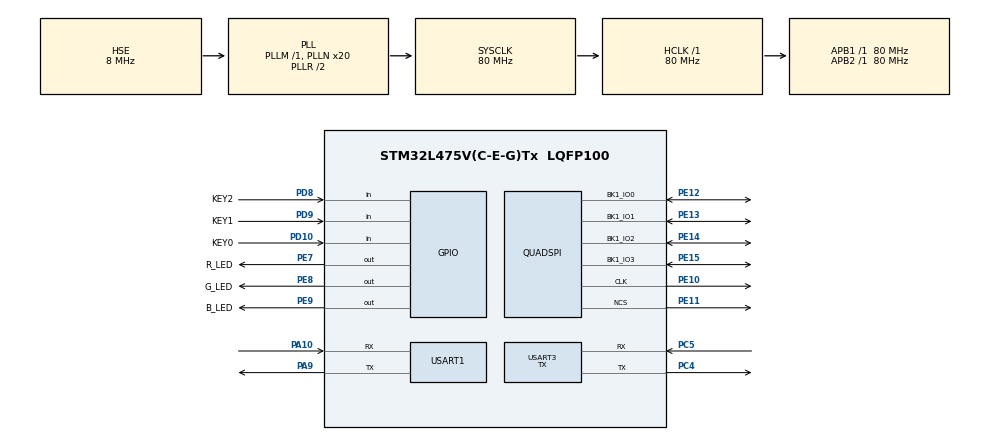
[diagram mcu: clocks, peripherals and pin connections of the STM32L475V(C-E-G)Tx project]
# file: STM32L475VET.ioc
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Dma.Request0=USART1_RX
Dma.Request1=USART1_TX
Dma.USART1_RX.0.Direction=DMA_PERIPH_TO_MEMORY
Dma.USART1_RX.0.Instance=DMA1_Channel5
Dma.USART1_RX.0.MemDataAlignment=DMA_MDATAALIGN_BYTE
Dma.USART1_RX.0.MemInc=DMA_MINC_ENABLE
Dma.USART1_RX.0.Mode=DMA_CIRCULAR
Dma.USART1_RX.0.PeriphDataAlignment=DMA_PDATAALIGN_BYTE
Dma.USART1_RX.0.PeriphInc=DMA_PINC_DISABLE
Dma.USART1_RX.0.Priority=DMA_PRIORITY_MEDIUM
Dma.USART1_TX.1.Direction=DMA_MEMORY_TO_PERIPH
Dma.USART1_TX.1.Instance=DMA1_Channel4
Dma.USART1_TX.1.MemDataAlignment=DMA_MDATAALIGN_BYTE
Dma.USART1_TX.1.MemInc=DMA_MINC_ENABLE
Dma.USART1_TX.1.Mode=DMA_NORMAL
Dma.USART1_TX.1.PeriphDataAlignment=DMA_PDATAALIGN_BYTE
Dma.USART1_TX.1.PeriphInc=DMA_PINC_DISABLE
Dma.USART1_TX.1.Priority=DMA_PRIORITY_LOW
Mcu.Family=STM32L4
Mcu.Name=STM32L475V(C-E-G)Tx
Mcu.Package=LQFP100
NVIC.DMA1_Channel4_IRQn=true\:1\:0\:true\:false\:false\:false\:true\:true
NVIC.DMA1_Channel5_IRQn=true\:1\:0\:true\:false\:false\:false\:true\:true
NVIC.PriorityGroup=NVIC_PRIORITYGROUP_4
NVIC.USART1_IRQn=true\:1\:0\:true\:false\:false\:true\:true\:true
PA10.Mode=Asynchronous
PA10.Signal=USART1_RX
PA13\ (JTMS-SWDIO).Mode=Serial_Wire
PA13\ (JTMS-SWDIO).Signal=SYS_JTMS-SWDIO
PA14\ (JTCK-SWCLK).Mode=Serial_Wire
PA14\ (JTCK-SWCLK).Signal=SYS_JTCK-SWCLK
PA9.Mode=Asynchronous
PA9.Signal=USART1_TX
PC4.Mode=Asynchronous
PC4.Signal=USART3_TX
PC5.Mode=Asynchronous
PC5.Signal=USART3_RX
PD10.GPIO_Label=KEY0
PD10.Signal=GPIO_Input
PD8.GPIO_Label=KEY2
PD8.Signal=GPIO_Input
PD9.GPIO_Label=KEY1
PD9.Signal=GPIO_Input
PE10.Mode=Single Bank
PE10.Signal=QUADSPI_CLK
PE11.Mode=Single Bank
PE11.Signal=QUADSPI_NCS
PE12.Mode=Single Bank
PE12.Signal=QUADSPI_BK1_IO0
PE13.Mode=Single Bank
PE13.Signal=QUADSPI_BK1_IO1
PE14.Mode=Single Bank
PE14.Signal=QUADSPI_BK1_IO2
PE15.Mode=Single Bank
PE15.Signal=QUADSPI_BK1_IO3
PE7.GPIO_Label=R_LED
PE7.GPIO_ModeDefaultOutputPP=GPIO_MODE_OUTPUT_PP
PE7.GPIO_PuPd=GPIO_NOPULL
PE7.GPIO_Speed=GPIO_SPEED_FREQ_HIGH
PE7.PinState=GPIO_PIN_SET
PE7.Signal=GPIO_Output
PE8.GPIO_Label=G_LED
PE8.GPIO_ModeDefaultOutputPP=GPIO_MODE_OUTPUT_PP
PE8.GPIO_PuPd=GPIO_NOPULL
PE8.GPIO_Speed=GPIO_SPEED_FREQ_HIGH
PE8.PinState=GPIO_PIN_SET
PE8.Signal=GPIO_Output
PE9.GPIO_Label=B_LED
PE9.GPIO_ModeDefaultOutputPP=GPIO_MODE_OUTPUT_PP
PE9.GPIO_PuPd=GPIO_NOPULL
PE9.GPIO_Speed=GPIO_SPEED_FREQ_HIGH
PE9.PinState=GPIO_PIN_SET
PE9.Signal=GPIO_Output
PH0-OSC_IN\ (PH0).Mode=HSE-External-Oscillator
PH0-OSC_IN\ (PH0).Signal=RCC_OSC_IN
PH1-OSC_OUT\ (PH1).Mode=HSE-External-Oscillator
PH1-OSC_OUT\ (PH1).Signal=RCC_OSC_OUT
ProjectManager.HeapSize=0x200
ProjectManager.StackSize=0x400
ProjectManager.TargetToolchain=MDK-ARM V5.32
QUADSPI.ChipSelectHighTime-Single\ Bank=QSPI_CS_HIGH_TIME_1_CYCLE
QUADSPI.ClockPrescaler-Single\ Bank=1
QUADSPI.FifoThreshold-Single\ Bank=1
QUADSPI.FlashSize-Single\ Bank=23
QUADSPI.SampleShifting-Single\ Bank=QSPI_SAMPLE_SHIFTING_HALFCYCLE
RCC.ADCFreq_Value=32000000
RCC.AHBFreq_Value=80000000
RCC.APB1Freq_Value=80000000
RCC.APB1TimFreq_Value=80000000
RCC.APB2Freq_Value=80000000
RCC.APB2TimFreq_Value=80000000
RCC.CortexFreq_Value=80000000
RCC.HCLKFreq_Value=80000000
RCC.HSE_VALUE=8000000
RCC.HSI_VALUE=16000000
RCC.LSE_VALUE=32768
RCC.MSI_VALUE=4000000
RCC.PLLN=20
RCC.PLLSourceVirtual=RCC_PLLSOURCE_HSE
RCC.SYSCLKFreq_VALUE=80000000
RCC.SYSCLKSource=RCC_SYSCLKSOURCE_PLLCLK
RCC.USBFreq_Value=32000000
RCC.VCOOutputFreq_Value=160000000
USART1.VirtualMode-Asynchronous=VM_ASYNC
USART3.Mode=MODE_TX
USART3.VirtualMode-Asynchronous=VM_ASYNC
board=custom

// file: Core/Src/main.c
/* USER CODE BEGIN Header */
/**
  ******************************************************************************
  * @file           : main.c
  * @brief          : Main program body
  ******************************************************************************
  * @attention
  *
  * Copyright (c) 2023 STMicroelectronics.
  * All rights reserved.
  *
  * This software is licensed under terms that can be found in the LICENSE file
  * in the root directory of this software component.
  * If no LICENSE file comes with this software, it is provided AS-IS.
  *
  ******************************************************************************
  */
/* USER CODE END Header */
#include "main.h"

QSPI_HandleTypeDef hqspi;

UART_HandleTypeDef huart1;
UART_HandleTypeDef huart3;
DMA_HandleTypeDef hdma_usart1_rx;
DMA_HandleTypeDef hdma_usart1_tx;

void SystemClock_Config(void);
static void MX_GPIO_Init(void);
static void MX_DMA_Init(void);
static void MX_USART1_UART_Init(void);
static void MX_USART3_UART_Init(void);
static void MX_QUADSPI_Init(void);
/* USER CODE BEGIN PFP */
extern void System_Init(void);
extern void APP_Init(void);
extern void APP_Running(void);
/* USER CODE END PFP */

int main(void)
{

  /* MCU Configuration--------------------------------------------------------*/

  /* Reset of all peripherals, Initializes the Flash interface and the Systick. */
  HAL_Init();

  /* Configure the system clock */
  SystemClock_Config();

  /* USER CODE BEGIN SysInit */
  System_Init();
  /* USER CODE END SysInit */

  /* Initialize all configured peripherals */
  MX_GPIO_Init();
  MX_DMA_Init();
  MX_USART1_UART_Init();
  MX_USART3_UART_Init();
  MX_QUADSPI_Init();
  /* USER CODE BEGIN 2 */
  APP_Init();
  /* USER CODE END 2 */

  /* Infinite loop */
  while (1)
  {

    /* USER CODE BEGIN 3 */
    APP_Running();
  }
  /* USER CODE END 3 */
}

void SystemClock_Config(void)
{
  RCC_OscInitTypeDef RCC_OscInitStruct = {0};
  RCC_ClkInitTypeDef RCC_ClkInitStruct = {0};

  /** Configure the main internal regulator output voltage
  */
  if (HAL_PWREx_ControlVoltageScaling(PWR_REGULATOR_VOLTAGE_SCALE1) != HAL_OK)
  {
    Error_Handler();
  }

  /** Initializes the RCC Oscillators according to the specified parameters
  * in the RCC_OscInitTypeDef structure.
  */
  RCC_OscInitStruct.OscillatorType = RCC_OSCILLATORTYPE_HSE;
  RCC_OscInitStruct.HSEState = RCC_HSE_ON;
  RCC_OscInitStruct.PLL.PLLState = RCC_PLL_ON;
  RCC_OscInitStruct.PLL.PLLSource = RCC_PLLSOURCE_HSE;
  RCC_OscInitStruct.PLL.PLLM = 1;
  RCC_OscInitStruct.PLL.PLLN = 20;
  RCC_OscInitStruct.PLL.PLLP = RCC_PLLP_DIV7;
  RCC_OscInitStruct.PLL.PLLQ = RCC_PLLQ_DIV2;
  RCC_OscInitStruct.PLL.PLLR = RCC_PLLR_DIV2;
  if (HAL_RCC_OscConfig(&RCC_OscInitStruct) != HAL_OK)
  {
    Error_Handler();
  }

  /** Initializes the CPU, AHB and APB buses clocks
  */
  RCC_ClkInitStruct.ClockType = RCC_CLOCKTYPE_HCLK|RCC_CLOCKTYPE_SYSCLK
                              |RCC_CLOCKTYPE_PCLK1|RCC_CLOCKTYPE_PCLK2;
  RCC_ClkInitStruct.SYSCLKSource = RCC_SYSCLKSOURCE_PLLCLK;
  RCC_ClkInitStruct.AHBCLKDivider = RCC_SYSCLK_DIV1;
  RCC_ClkInitStruct.APB1CLKDivider = RCC_HCLK_DIV1;
  RCC_ClkInitStruct.APB2CLKDivider = RCC_HCLK_DIV1;

  if (HAL_RCC_ClockConfig(&RCC_ClkInitStruct, FLASH_LATENCY_4) != HAL_OK)
  {
    Error_Handler();
  }
}

static void MX_QUADSPI_Init(void)
{

  /* QUADSPI parameter configuration*/
  hqspi.Instance = QUADSPI;
  hqspi.Init.ClockPrescaler = 1;
  hqspi.Init.FifoThreshold = 1;
  hqspi.Init.SampleShifting = QSPI_SAMPLE_SHIFTING_HALFCYCLE;
  hqspi.Init.FlashSize = 23;
  hqspi.Init.ChipSelectHighTime = QSPI_CS_HIGH_TIME_1_CYCLE;
  hqspi.Init.ClockMode = QSPI_CLOCK_MODE_0;
  if (HAL_QSPI_Init(&hqspi) != HAL_OK)
  {
    Error_Handler();
  }

}

static void MX_USART1_UART_Init(void)
{

  huart1.Instance = USART1;
  huart1.Init.BaudRate = 115200;
  huart1.Init.WordLength = UART_WORDLENGTH_8B;
  huart1.Init.StopBits = UART_STOPBITS_1;
  huart1.Init.Parity = UART_PARITY_NONE;
  huart1.Init.Mode = UART_MODE_TX_RX;
  huart1.Init.HwFlowCtl = UART_HWCONTROL_NONE;
  huart1.Init.OverSampling = UART_OVERSAMPLING_16;
  huart1.Init.OneBitSampling = UART_ONE_BIT_SAMPLE_DISABLE;
  huart1.AdvancedInit.AdvFeatureInit = UART_ADVFEATURE_NO_INIT;
  if (HAL_UART_Init(&huart1) != HAL_OK)
  {
    Error_Handler();
  }

}

static void MX_USART3_UART_Init(void)
{

  huart3.Instance = USART3;
  huart3.Init.BaudRate = 115200;
  huart3.Init.WordLength = UART_WORDLENGTH_8B;
  huart3.Init.StopBits = UART_STOPBITS_1;
  huart3.Init.Parity = UART_PARITY_NONE;
  huart3.Init.Mode = UART_MODE_TX;
  huart3.Init.HwFlowCtl = UART_HWCONTROL_NONE;
  huart3.Init.OverSampling = UART_OVERSAMPLING_16;
  huart3.Init.OneBitSampling = UART_ONE_BIT_SAMPLE_DISABLE;
  huart3.AdvancedInit.AdvFeatureInit = UART_ADVFEATURE_NO_INIT;
  if (HAL_UART_Init(&huart3) != HAL_OK)
  {
    Error_Handler();
  }

}

static void MX_DMA_Init(void)
{

  /* DMA controller clock enable */
  __HAL_RCC_DMA1_CLK_ENABLE();

  /* DMA interrupt init */
  /* DMA1_Channel4_IRQn interrupt configuration */
  HAL_NVIC_SetPriority(DMA1_Channel4_IRQn, 1, 0);
  HAL_NVIC_EnableIRQ(DMA1_Channel4_IRQn);
  /* DMA1_Channel5_IRQn interrupt configuration */
  HAL_NVIC_SetPriority(DMA1_Channel5_IRQn, 1, 0);
  HAL_NVIC_EnableIRQ(DMA1_Channel5_IRQn);

}

static void MX_GPIO_Init(void)
{
  GPIO_InitTypeDef GPIO_InitStruct = {0};

  /* GPIO Ports Clock Enable */
  __HAL_RCC_GPIOH_CLK_ENABLE();
  __HAL_RCC_GPIOC_CLK_ENABLE();
  __HAL_RCC_GPIOE_CLK_ENABLE();
  __HAL_RCC_GPIOD_CLK_ENABLE();
  __HAL_RCC_GPIOA_CLK_ENABLE();

  /*Configure GPIO pin Output Level */
  HAL_GPIO_WritePin(GPIOE, R_LED_Pin|G_LED_Pin|B_LED_Pin, GPIO_PIN_SET);

  /*Configure GPIO pins : R_LED_Pin G_LED_Pin B_LED_Pin */
  GPIO_InitStruct.Pin = R_LED_Pin|G_LED_Pin|B_LED_Pin;
  GPIO_InitStruct.Mode = GPIO_MODE_OUTPUT_PP;
  GPIO_InitStruct.Pull = GPIO_NOPULL;
  GPIO_InitStruct.Speed = GPIO_SPEED_FREQ_HIGH;
  HAL_GPIO_Init(GPIOE, &GPIO_InitStruct);

  /*Configure GPIO pins : KEY2_Pin KEY1_Pin KEY0_Pin */
  GPIO_InitStruct.Pin = KEY2_Pin|KEY1_Pin|KEY0_Pin;
  GPIO_InitStruct.Mode = GPIO_MODE_INPUT;
  GPIO_InitStruct.Pull = GPIO_NOPULL;
  HAL_GPIO_Init(GPIOD, &GPIO_InitStruct);

}

void Error_Handler(void)
{
  __disable_irq();
  while (1)
  {
  }
}
